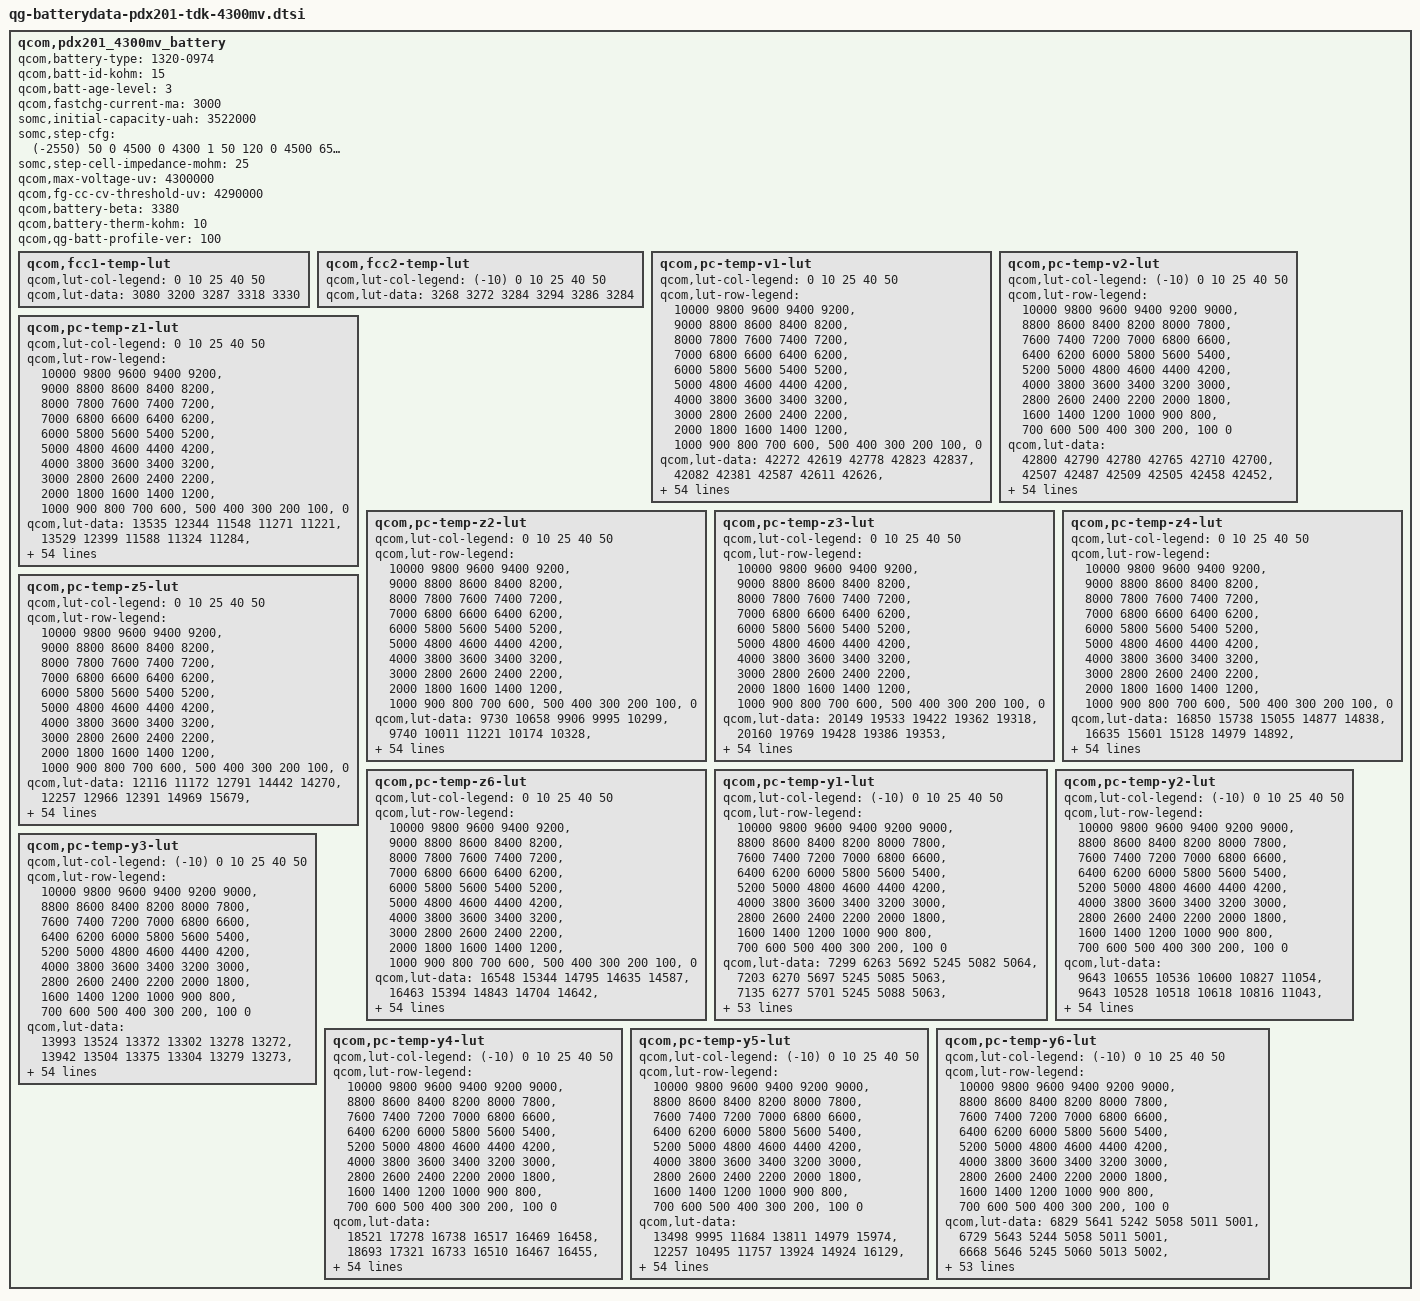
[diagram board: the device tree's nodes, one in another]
// SPDX-License-Identifier: GPL-2.0-only
/*
 * Copyright (c) 2019, The Linux Foundation. All rights reserved.
 */

qcom,pdx201_4300mv_battery {
	/* Added or Modified by SOMC */
	qcom,battery-type = "1320-0974";
	qcom,batt-id-kohm = <15>;
	qcom,batt-age-level = <3>;
	qcom,fastchg-current-ma = <3000>;
	somc,initial-capacity-uah = <3522000>;
	somc,step-cfg = <
		(-2550) 50    0 4500    0 4300 1
		   50  120    0 4500  650 4300 2
		  120  200    0 4100 2050 4300 3
		  120  200 4100 4200 1350 4300 3
		  120  200 4200 4500 1200 4300 3
		  200  450    0 4150 2750 4300 3
		  200  450 4150 4200 2050 4300 3
		  200  450 4200 4500 1350 4300 3
		  450  550    0 4500 1000 4200 4
		  550 2550    0 4500    0 4200 5
	>;
	somc,step-cell-impedance-mohm = <25>;

	/* Prepared by Qualcomm */
	/* 4176715_SoMC_Amuro2_3254mAh_averaged_MasterSlave_Sept16th2019 */
	qcom,max-voltage-uv = <4300000>;
	qcom,fg-cc-cv-threshold-uv = <4290000>;
	/* qcom,fastchg-current-ma = <1500>; */
	/* qcom,batt-id-kohm = <330>; */
	qcom,battery-beta = <3380>;
	qcom,battery-therm-kohm = <10>;
	/* qcom,battery-type = "4176715_SoMC_Amuro2_3254mAh_averaged_MasterSlave_Sept16th2019"; */
	qcom,qg-batt-profile-ver = <100>;

	qcom,fcc1-temp-lut {
		qcom,lut-col-legend = <0 10 25 40 50>;
		qcom,lut-data = <3080 3200 3287 3318 3330>;
	};

	qcom,fcc2-temp-lut {
		qcom,lut-col-legend = <(-10) 0 10 25 40 50>;
		qcom,lut-data = <3268 3272 3284 3294 3286 3284>;
	};

	qcom,pc-temp-v1-lut {
		qcom,lut-col-legend = <0 10 25 40 50>;
		qcom,lut-row-legend = <10000 9800 9600 9400 9200>,
			<9000 8800 8600 8400 8200>,
			<8000 7800 7600 7400 7200>,
			<7000 6800 6600 6400 6200>,
			<6000 5800 5600 5400 5200>,
			<5000 4800 4600 4400 4200>,
			<4000 3800 3600 3400 3200>,
			<3000 2800 2600 2400 2200>,
			<2000 1800 1600 1400 1200>,
			<1000 900 800 700 600>,
			<500 400 300 200 100>,
			<0>;
		qcom,lut-data = <42272 42619 42778 42823 42837>,
			<42082 42381 42587 42611 42626>,
			<41894 42162 42359 42397 42415>,
			<41706 41964 42130 42180 42200>,
			<41514 41775 41918 41967 41988>,
			<41341 41578 41712 41756 41780>,
			<41214 41380 41509 41549 41573>,
			<41105 41211 41305 41342 41367>,
			<40944 41092 41124 41144 41164>,
			<40609 40969 40992 40972 40968>,
			<40246 40739 40864 40819 40781>,
			<40040 40372 40651 40642 40595>,
			<39901 40092 40314 40404 40409>,
			<39788 39946 40061 40171 40228>,
			<39689 39832 39944 40010 40061>,
			<39603 39727 39851 39882 39906>,
			<39509 39635 39734 39750 39755>,
			<39402 39535 39601 39613 39615>,
			<39292 39414 39460 39466 39471>,
			<39184 39279 39314 39297 39306>,
			<39077 39134 39156 39113 39125>,
			<38973 38975 38962 38942 38955>,
			<38869 38819 38731 38770 38789>,
			<38768 38660 38578 38624 38641>,
			<38670 38510 38498 38524 38531>,
			<38573 38423 38437 38443 38441>,
			<38486 38372 38375 38363 38355>,
			<38419 38331 38318 38286 38272>,
			<38362 38293 38262 38215 38197>,
			<38318 38258 38208 38151 38130>,
			<38283 38225 38158 38094 38071>,
			<38255 38194 38115 38046 38018>,
			<38231 38164 38078 38006 37972>,
			<38212 38137 38043 37966 37927>,
			<38193 38112 38013 37928 37882>,
			<38168 38083 37981 37888 37836>,
			<38139 38051 37944 37841 37782>,
			<38099 38011 37904 37787 37722>,
			<38031 37950 37846 37721 37651>,
			<37943 37858 37755 37637 37569>,
			<37844 37755 37646 37538 37473>,
			<37727 37639 37531 37424 37359>,
			<37595 37510 37401 37295 37228>,
			<37449 37362 37254 37150 37082>,
			<37342 37251 37137 37034 36968>,
			<37279 37184 37069 36969 36906>,
			<37257 37163 37052 36954 36889>,
			<37238 37145 37040 36940 36875>,
			<37206 37123 37018 36915 36848>,
			<37084 37032 36919 36796 36711>,
			<36755 36717 36609 36478 36385>,
			<36307 36278 36178 36042 35948>,
			<35743 35718 35619 35483 35387>,
			<34994 34955 34864 34723 34627>,
			<33801 33785 33698 33556 33460>,
			<30000 30000 30000 30000 30000>;
	};

	qcom,pc-temp-v2-lut {
		qcom,lut-col-legend = <(-10) 0 10 25 40 50>;
		qcom,lut-row-legend = <10000 9800 9600 9400 9200 9000>,
			<8800 8600 8400 8200 8000 7800>,
			<7600 7400 7200 7000 6800 6600>,
			<6400 6200 6000 5800 5600 5400>,
			<5200 5000 4800 4600 4400 4200>,
			<4000 3800 3600 3400 3200 3000>,
			<2800 2600 2400 2200 2000 1800>,
			<1600 1400 1200 1000 900 800>,
			<700 600 500 400 300 200>,
			<100 0>;
		qcom,lut-data = <42800 42790 42780 42765 42710 42700>,
			<42507 42487 42509 42505 42458 42452>,
			<42226 42213 42256 42261 42219 42216>,
			<41949 41971 42027 42034 41995 41992>,
			<41664 41758 41818 41824 41783 41780>,
			<41456 41552 41615 41618 41577 41573>,
			<41354 41334 41403 41407 41371 41368>,
			<41272 41127 41201 41204 41170 41167>,
			<41134 40974 41038 41029 40978 40972>,
			<40922 40864 40910 40877 40797 40781>,
			<40655 40719 40748 40701 40608 40594>,
			<40243 40411 40466 40445 40394 40408>,
			<39810 40044 40151 40181 40184 40228>,
			<39613 39812 39933 39997 40021 40062>,
			<39513 39648 39762 39853 39889 39906>,
			<39406 39503 39610 39720 39755 39754>,
			<39270 39370 39479 39601 39614 39608>,
			<39106 39243 39350 39477 39467 39460>,
			<38848 39097 39190 39313 39299 39293>,
			<38447 38935 39004 39113 39109 39109>,
			<38205 38783 38838 38926 38927 38930>,
			<38138 38649 38698 38752 38751 38755>,
			<38095 38524 38575 38600 38594 38597>,
			<38051 38398 38466 38483 38476 38478>,
			<38012 38272 38370 38385 38378 38379>,
			<37973 38155 38282 38296 38290 38290>,
			<37933 38037 38202 38214 38208 38206>,
			<37894 37940 38126 38140 38134 38129>,
			<37856 37892 38045 38071 38065 38059>,
			<37819 37862 37962 38007 38001 37995>,
			<37781 37833 37899 37949 37943 37936>,
			<37745 37803 37851 37897 37892 37885>,
			<37708 37772 37810 37847 37841 37832>,
			<37671 37737 37771 37797 37779 37765>,
			<37633 37700 37735 37747 37711 37686>,
			<37592 37660 37696 37690 37636 37598>,
			<37550 37621 37655 37625 37551 37498>,
			<37502 37577 37608 37557 37468 37402>,
			<37440 37519 37550 37492 37399 37330>,
			<37364 37448 37480 37424 37335 37266>,
			<37285 37367 37400 37342 37257 37189>,
			<37203 37268 37300 37240 37157 37091>,
			<37123 37157 37184 37124 37043 36977>,
			<37051 37034 37052 36998 36915 36849>,
			<36980 36935 36943 36902 36832 36776>,
			<36900 36872 36899 36874 36809 36752>,
			<36856 36840 36881 36857 36793 36734>,
			<36804 36803 36858 36830 36766 36711>,
			<36732 36748 36816 36782 36712 36651>,
			<36587 36624 36701 36618 36533 36451>,
			<36311 36343 36389 36246 36165 36071>,
			<35881 35898 35915 35768 35676 35578>,
			<35287 35304 35313 35148 35051 34948>,
			<34450 34497 34516 34293 34196 34090>,
			<33193 33338 33386 33060 32908 32784>,
			<29549 29531 29522 29521 29519 29517>;
	};

	qcom,pc-temp-z1-lut {
		qcom,lut-col-legend = <0 10 25 40 50>;
		qcom,lut-row-legend = <10000 9800 9600 9400 9200>,
			<9000 8800 8600 8400 8200>,
			<8000 7800 7600 7400 7200>,
			<7000 6800 6600 6400 6200>,
			<6000 5800 5600 5400 5200>,
			<5000 4800 4600 4400 4200>,
			<4000 3800 3600 3400 3200>,
			<3000 2800 2600 2400 2200>,
			<2000 1800 1600 1400 1200>,
			<1000 900 800 700 600>,
			<500 400 300 200 100>,
			<0>;
		qcom,lut-data = <13535 12344 11548 11271 11221>,
			<13529 12399 11588 11324 11284>,
			<13530 12417 11610 11344 11303>,
			<13538 12417 11621 11358 11314>,
			<13559 12418 11625 11365 11322>,
			<13576 12422 11628 11371 11328>,
			<13583 12433 11633 11374 11332>,
			<13589 12438 11638 11376 11333>,
			<13587 12437 11641 11377 11334>,
			<13576 12434 11640 11379 11335>,
			<13563 12426 11638 11381 11335>,
			<13548 12406 11633 11381 11335>,
			<13530 12392 11623 11379 11336>,
			<13515 12386 11618 11376 11337>,
			<13506 12383 11623 11378 11338>,
			<13498 12388 11631 11382 11340>,
			<13498 12409 11636 11384 11341>,
			<13521 12425 11640 11385 11342>,
			<13545 12431 11644 11386 11343>,
			<13542 12436 11646 11387 11343>,
			<13524 12439 11647 11388 11344>,
			<13514 12442 11651 11389 11344>,
			<13514 12443 11656 11391 11346>,
			<13513 12445 11660 11392 11347>,
			<13511 12447 11662 11394 11350>,
			<13506 12449 11664 11396 11353>,
			<13502 12455 11668 11398 11355>,
			<13511 12461 11673 11401 11357>,
			<13536 12466 11677 11404 11358>,
			<13553 12478 11680 11407 11360>,
			<13558 12480 11683 11410 11362>,
			<13559 12474 11687 11411 11363>,
			<13556 12469 11691 11412 11364>,
			<13542 12473 11694 11413 11364>,
			<13531 12483 11696 11415 11365>,
			<13546 12491 11698 11417 11365>,
			<13579 12498 11700 11417 11366>,
			<13593 12503 11702 11417 11367>,
			<13573 12509 11704 11418 11368>,
			<13547 12516 11705 11419 11369>,
			<13539 12521 11707 11420 11369>,
			<13535 12525 11710 11421 11370>,
			<13532 12528 11713 11421 11371>,
			<13533 12515 11714 11422 11371>,
			<13527 12522 11716 11422 11371>,
			<13539 12521 11722 11424 11372>,
			<13527 12528 11718 11423 11371>,
			<13548 12531 11719 11422 11370>,
			<13548 12503 11718 11423 11371>,
			<13512 12540 11723 11422 11372>,
			<13542 12558 11729 11425 11373>,
			<13606 12561 11737 11431 11379>,
			<13602 12586 11754 11440 11384>,
			<13636 12641 11783 11454 11394>,
			<13636 12641 11783 11454 11394>,
			<13636 12641 11783 11454 11394>;
	};

	qcom,pc-temp-z2-lut {
		qcom,lut-col-legend = <0 10 25 40 50>;
		qcom,lut-row-legend = <10000 9800 9600 9400 9200>,
			<9000 8800 8600 8400 8200>,
			<8000 7800 7600 7400 7200>,
			<7000 6800 6600 6400 6200>,
			<6000 5800 5600 5400 5200>,
			<5000 4800 4600 4400 4200>,
			<4000 3800 3600 3400 3200>,
			<3000 2800 2600 2400 2200>,
			<2000 1800 1600 1400 1200>,
			<1000 900 800 700 600>,
			<500 400 300 200 100>,
			<0>;
		qcom,lut-data = <9730 10658 9906 9995 10299>,
			<9740 10011 11221 10174 10328>,
			<9752 9800 10793 10559 10389>,
			<9768 9797 10388 10917 10473>,
			<9788 9796 10200 10935 10471>,
			<9806 9794 10038 10836 10367>,
			<9818 9793 10013 10769 10298>,
			<9829 9793 10006 10709 10302>,
			<9832 9808 10005 10639 10310>,
			<9819 9825 10137 10620 10315>,
			<9802 9830 10362 10619 10325>,
			<9797 9831 10488 10637 10333>,
			<9794 9834 10576 10781 10343>,
			<9794 9845 10606 10914 10360>,
			<9795 9865 10379 10744 10386>,
			<9797 9885 10085 10349 10425>,
			<9798 9910 10062 10235 10441>,
			<9794 9934 10120 10228 10427>,
			<9791 9957 10159 10223 10410>,
			<9795 9979 10172 10310 10415>,
			<9809 9998 10179 10481 10431>,
			<9823 10015 10173 10504 10436>,
			<9831 10028 10155 10336 10420>,
			<9839 10039 10148 10214 10406>,
			<9847 10048 10151 10243 10441>,
			<9859 10048 10157 10309 10518>,
			<9868 10036 10184 10371 10529>,
			<9871 10026 10239 10443 10464>,
			<9872 10026 10260 10477 10405>,
			<9873 10026 10256 10426 10350>,
			<9875 10027 10249 10357 10286>,
			<9876 10035 10240 10350 10279>,
			<9877 10043 10228 10361 10303>,
			<9877 10047 10225 10377 10339>,
			<9878 10051 10240 10429 10420>,
			<9881 10054 10258 10494 10510>,
			<9889 10058 10272 10537 10548>,
			<9899 10064 10285 10574 10571>,
			<9910 10074 10298 10594 10587>,
			<9924 10089 10317 10603 10610>,
			<9938 10097 10330 10607 10629>,
			<9952 10098 10333 10607 10626>,
			<9974 10099 10337 10607 10618>,
			<10018 10119 10348 10611 10592>,
			<10246 10244 10403 10595 10589>,
			<10258 10290 10437 10534 10643>,
			<10247 10285 10423 10543 10622>,
			<10247 10289 10419 10540 10650>,
			<10264 10312 10418 10585 10740>,
			<10290 10340 10500 10740 10681>,
			<10288 10334 10486 10573 10498>,
			<10213 10285 10449 10483 10386>,
			<10106 10265 10386 10438 10333>,
			<9771 10215 10290 10334 10278>,
			<9771 10215 10290 10334 10278>,
			<9771 10215 10290 10334 10278>;
	};

	qcom,pc-temp-z3-lut {
		qcom,lut-col-legend = <0 10 25 40 50>;
		qcom,lut-row-legend = <10000 9800 9600 9400 9200>,
			<9000 8800 8600 8400 8200>,
			<8000 7800 7600 7400 7200>,
			<7000 6800 6600 6400 6200>,
			<6000 5800 5600 5400 5200>,
			<5000 4800 4600 4400 4200>,
			<4000 3800 3600 3400 3200>,
			<3000 2800 2600 2400 2200>,
			<2000 1800 1600 1400 1200>,
			<1000 900 800 700 600>,
			<500 400 300 200 100>,
			<0>;
		qcom,lut-data = <20149 19533 19422 19362 19318>,
			<20160 19769 19428 19386 19353>,
			<20165 19845 19496 19415 19371>,
			<20161 19840 19545 19436 19382>,
			<20133 19835 19549 19448 19383>,
			<20093 19837 19550 19457 19377>,
			<20020 19844 19549 19459 19371>,
			<19916 19845 19542 19447 19368>,
			<19881 19795 19538 19428 19365>,
			<19943 19736 19543 19414 19359>,
			<20014 19737 19552 19401 19349>,
			<20016 19762 19559 19397 19343>,
			<19980 19776 19565 19401 19342>,
			<19947 19744 19567 19405 19342>,
			<19933 19694 19501 19394 19339>,
			<19922 19668 19416 19369 19332>,
			<19922 19651 19408 19361 19329>,
			<19952 19643 19422 19362 19327>,
			<19985 19648 19440 19364 19327>,
			<19991 19659 19465 19374 19332>,
			<19989 19677 19490 19391 19345>,
			<19988 19712 19502 19394 19349>,
			<19993 19741 19510 19379 19332>,
			<20000 19752 19512 19364 19318>,
			<20006 19761 19499 19358 19321>,
			<20015 19760 19482 19354 19332>,
			<20021 19744 19474 19359 19345>,
			<20019 19725 19468 19389 19364>,
			<20010 19710 19468 19411 19375>,
			<20001 19697 19492 19415 19374>,
			<19990 19691 19515 19417 19368>,
			<19978 19690 19516 19415 19365>,
			<19967 19689 19513 19406 19360>,
			<19955 19690 19509 19398 19356>,
			<19944 19691 19502 19392 19354>,
			<19935 19691 19496 19388 19351>,
			<19928 19688 19492 19388 19349>,
			<19921 19684 19488 19389 19347>,
			<19914 19679 19485 19390 19345>,
			<19906 19672 19480 19382 19342>,
			<19894 19666 19476 19375 19340>,
			<19874 19662 19473 19373 19340>,
			<19850 19656 19469 19373 19341>,
			<19813 19639 19465 19370 19342>,
			<19676 19573 19445 19362 19339>,
			<19655 19544 19427 19351 19327>,
			<19649 19540 19426 19344 19325>,
			<19638 19537 19414 19340 19323>,
			<19620 19529 19409 19335 19315>,
			<19612 19516 19396 19327 19330>,
			<19613 19513 19397 19342 19343>,
			<19620 19516 19395 19346 19350>,
			<19575 19481 19394 19347 19352>,
			<19417 19465 19380 19357 19359>,
			<19417 19465 19380 19357 19359>,
			<19417 19465 19380 19357 19359>;
	};

	qcom,pc-temp-z4-lut {
		qcom,lut-col-legend = <0 10 25 40 50>;
		qcom,lut-row-legend = <10000 9800 9600 9400 9200>,
			<9000 8800 8600 8400 8200>,
			<8000 7800 7600 7400 7200>,
			<7000 6800 6600 6400 6200>,
			<6000 5800 5600 5400 5200>,
			<5000 4800 4600 4400 4200>,
			<4000 3800 3600 3400 3200>,
			<3000 2800 2600 2400 2200>,
			<2000 1800 1600 1400 1200>,
			<1000 900 800 700 600>,
			<500 400 300 200 100>,
			<0>;
		qcom,lut-data = <16850 15738 15055 14877 14838>,
			<16635 15601 15128 14979 14892>,
			<16450 15482 15066 14947 14898>,
			<16302 15375 15003 14880 14859>,
			<16178 15281 14964 14833 14829>,
			<16072 15204 14929 14792 14806>,
			<15983 15137 14899 14770 14788>,
			<15904 15086 14875 14763 14775>,
			<15824 15049 14844 14758 14765>,
			<15737 15017 14777 14751 14757>,
			<15649 14983 14709 14737 14751>,
			<15570 14947 14698 14724 14744>,
			<15497 14928 14701 14715 14733>,
			<15427 14924 14705 14708 14721>,
			<15363 14921 14751 14710 14711>,
			<15303 14914 14807 14714 14703>,
			<15241 14900 14807 14710 14695>,
			<15171 14886 14780 14697 14686>,
			<15111 14875 14759 14689 14680>,
			<15075 14866 14745 14700 14689>,
			<15048 14865 14736 14730 14720>,
			<15032 14870 14769 14766 14756>,
			<15025 14879 14877 14838 14821>,
			<15020 14915 14925 14887 14870>,
			<15020 14968 14922 14885 14862>,
			<15029 14981 14916 14876 14836>,
			<15040 14979 14908 14856 14807>,
			<15049 14975 14896 14807 14769>,
			<15058 14969 14878 14764 14739>,
			<15061 14962 14837 14741 14723>,
			<15060 14953 14798 14725 14712>,
			<15058 14939 14783 14716 14702>,
			<15054 14924 14773 14709 14693>,
			<15048 14912 14770 14707 14689>,
			<15040 14901 14769 14709 14693>,
			<15031 14897 14769 14712 14701>,
			<15022 14897 14771 14719 14714>,
			<15016 14899 14777 14730 14732>,
			<15014 14904 14786 14741 14739>,
			<15012 14915 14802 14751 14739>,
			<15009 14920 14813 14758 14737>,
			<15003 14913 14812 14756 14733>,
			<14991 14901 14809 14751 14727>,
			<14960 14886 14805 14755 14730>,
			<14863 14829 14781 14748 14727>,
			<14847 14791 14738 14718 14702>,
			<14841 14781 14726 14705 14685>,
			<14836 14773 14720 14686 14661>,
			<14828 14768 14714 14682 14661>,
			<14828 14777 14740 14715 14673>,
			<14849 14798 14759 14714 14667>,
			<14853 14801 14763 14710 14662>,
			<14903 14827 14763 14707 14658>,
			<15068 14829 14772 14694 14650>,
			<15068 14829 14772 14694 14650>,
			<15068 14829 14772 14694 14650>;
	};

	qcom,pc-temp-z5-lut {
		qcom,lut-col-legend = <0 10 25 40 50>;
		qcom,lut-row-legend = <10000 9800 9600 9400 9200>,
			<9000 8800 8600 8400 8200>,
			<8000 7800 7600 7400 7200>,
			<7000 6800 6600 6400 6200>,
			<6000 5800 5600 5400 5200>,
			<5000 4800 4600 4400 4200>,
			<4000 3800 3600 3400 3200>,
			<3000 2800 2600 2400 2200>,
			<2000 1800 1600 1400 1200>,
			<1000 900 800 700 600>,
			<500 400 300 200 100>,
			<0>;
		qcom,lut-data = <12116 11172 12791 14442 14270>,
			<12257 12966 12391 14969 15679>,
			<12370 13735 13760 15632 16042>,
			<12446 13926 15068 16622 16541>,
			<12524 14076 15586 17782 16686>,
			<12563 14457 15957 19271 16487>,
			<12430 15064 16257 19970 16372>,
			<12160 15286 16494 19749 16541>,
			<12080 14743 16916 19278 16753>,
			<12619 14111 19508 19157 16718>,
			<13239 14565 23162 19073 16329>,
			<13324 16425 24639 19125 16098>,
			<13315 17403 25404 20362 16493>,
			<13309 16616 25581 21617 17043>,
			<13373 15555 20730 20633 17168>,
			<13556 15407 14417 18173 17198>,
			<13870 15557 13783 17779 17268>,
			<14845 15800 14811 18688 17770>,
			<16111 16482 16493 20185 18756>,
			<17136 17816 21366 25028 21324>,
			<18104 20260 26692 32419 25830>,
			<19163 25759 28874 33288 26876>,
			<20447 29897 30570 25880 21281>,
			<21867 31213 31004 19178 15973>,
			<23302 32192 26558 16726 15122>,
			<25064 31958 20940 15162 14705>,
			<26242 28196 18637 15133 14851>,
			<26194 24240 17146 16495 16664>,
			<25789 22302 16823 18245 18294>,
			<25284 20876 18599 20310 19044>,
			<24552 20533 20951 22477 19937>,
			<23702 20651 22437 23954 20991>,
			<23033 20865 23677 25145 22752>,
			<22377 21344 24266 25699 23974>,
			<21981 22155 24556 25869 24628>,
			<21997 22571 24693 25956 25068>,
			<22148 22735 24390 25825 24399>,
			<22335 22826 23528 25278 21819>,
			<22985 22649 22574 24395 19766>,
			<23692 22135 21304 21524 18393>,
			<23719 21903 20291 18776 17503>,
			<23385 22074 19890 18220 17304>,
			<23406 22200 19644 17936 17191>,
			<24180 22186 19323 17136 16799>,
			<25559 22646 19572 16913 16429>,
			<24591 22988 20610 17363 16350>,
			<23739 22871 20861 17023 17015>,
			<22738 23262 19713 17693 18911>,
			<21972 22830 19890 17874 18397>,
			<21910 21126 17533 15017 17015>,
			<20615 19108 15996 14868 17764>,
			<19060 18220 15370 14968 18751>,
			<15601 15278 14926 14908 19396>,
			<11826 14317 13982 15783 21490>,
			<11826 14317 13982 15783 21490>,
			<11826 14317 13982 15783 21490>;
	};

	qcom,pc-temp-z6-lut {
		qcom,lut-col-legend = <0 10 25 40 50>;
		qcom,lut-row-legend = <10000 9800 9600 9400 9200>,
			<9000 8800 8600 8400 8200>,
			<8000 7800 7600 7400 7200>,
			<7000 6800 6600 6400 6200>,
			<6000 5800 5600 5400 5200>,
			<5000 4800 4600 4400 4200>,
			<4000 3800 3600 3400 3200>,
			<3000 2800 2600 2400 2200>,
			<2000 1800 1600 1400 1200>,
			<1000 900 800 700 600>,
			<500 400 300 200 100>,
			<0>;
		qcom,lut-data = <16548 15344 14795 14635 14587>,
			<16463 15394 14843 14704 14642>,
			<16384 15402 14851 14703 14651>,
			<16310 15358 14854 14694 14646>,
			<16243 15301 14845 14686 14639>,
			<16176 15269 14826 14675 14627>,
			<16093 15245 14811 14664 14616>,
			<16006 15217 14798 14653 14608>,
			<15959 15172 14783 14642 14602>,
			<15942 15130 14757 14631 14595>,
			<15928 15116 14733 14617 14587>,
			<15898 15109 14730 14611 14580>,
			<15844 15100 14733 14609 14575>,
			<15793 15080 14735 14607 14569>,
			<15756 15056 14720 14601 14563>,
			<15725 15040 14699 14589 14556>,
			<15705 15027 14693 14581 14550>,
			<15693 15021 14690 14576 14545>,
			<15683 15022 14689 14573 14542>,
			<15671 15023 14694 14582 14548>,
			<15659 15029 14704 14604 14569>,
			<15653 15048 14729 14622 14586>,
			<15654 15072 14779 14645 14606>,
			<15656 15098 14800 14659 14620>,
			<15660 15123 14793 14656 14619>,
			<15670 15128 14782 14650 14614>,
			<15679 15120 14774 14645 14609>,
			<15679 15109 14767 14639 14603>,
			<15679 15101 14761 14634 14596>,
			<15678 15092 14756 14627 14589>,
			<15675 15085 14751 14621 14581>,
			<15669 15078 14746 14614 14574>,
			<15663 15073 14741 14606 14567>,
			<15655 15069 14736 14602 14564>,
			<15648 15067 14732 14600 14564>,
			<15641 15065 14729 14598 14565>,
			<15634 15065 14729 14600 14568>,
			<15630 15065 14730 14607 14575>,
			<15626 15065 14731 14610 14578>,
			<15623 15068 14735 14610 14576>,
			<15616 15069 14739 14610 14574>,
			<15603 15065 14738 14609 14572>,
			<15585 15058 14734 14606 14570>,
			<15553 15044 14730 14606 14572>,
			<15441 14988 14710 14600 14569>,
			<15422 14957 14683 14580 14552>,
			<15415 14951 14677 14571 14543>,
			<15407 14945 14667 14561 14532>,
			<15399 14940 14662 14556 14527>,
			<15401 14941 14667 14566 14541>,
			<15420 14953 14678 14574 14547>,
			<15436 14961 14681 14577 14549>,
			<15454 14967 14685 14578 14550>,
			<15479 14978 14688 14580 14553>,
			<15479 14978 14688 14580 14553>,
			<15479 14978 14688 14580 14553>;
	};

	qcom,pc-temp-y1-lut {
		qcom,lut-col-legend = <(-10) 0 10 25 40 50>;
		qcom,lut-row-legend = <10000 9800 9600 9400 9200 9000>,
			<8800 8600 8400 8200 8000 7800>,
			<7600 7400 7200 7000 6800 6600>,
			<6400 6200 6000 5800 5600 5400>,
			<5200 5000 4800 4600 4400 4200>,
			<4000 3800 3600 3400 3200 3000>,
			<2800 2600 2400 2200 2000 1800>,
			<1600 1400 1200 1000 900 800>,
			<700 600 500 400 300 200>,
			<100 0>;
		qcom,lut-data = <7299 6263 5692 5245 5082 5064>,
			<7203 6270 5697 5245 5085 5063>,
			<7135 6277 5701 5245 5088 5063>,
			<7092 6281 5702 5244 5090 5063>,
			<7068 6283 5703 5243 5091 5063>,
			<7061 6282 5703 5242 5091 5063>,
			<7087 6276 5698 5241 5090 5063>,
			<7124 6269 5691 5239 5089 5063>,
			<7119 6266 5689 5237 5089 5063>,
			<7065 6264 5688 5236 5088 5062>,
			<7034 6264 5688 5235 5089 5062>,
			<7052 6257 5686 5236 5089 5063>,
			<7078 6247 5685 5238 5089 5065>,
			<7079 6252 5685 5241 5090 5065>,
			<7060 6270 5687 5245 5090 5064>,
			<7049 6281 5688 5247 5091 5063>,
			<7060 6278 5688 5246 5092 5063>,
			<7073 6273 5688 5244 5093 5063>,
			<7069 6271 5688 5245 5093 5064>,
			<7051 6266 5690 5246 5092 5064>,
			<7040 6264 5693 5248 5092 5065>,
			<7049 6268 5700 5251 5092 5066>,
			<7065 6272 5706 5254 5092 5067>,
			<7083 6278 5706 5255 5094 5067>,
			<7121 6292 5704 5256 5096 5068>,
			<7138 6302 5703 5258 5097 5069>,
			<7107 6307 5705 5262 5098 5070>,
			<7067 6311 5708 5266 5099 5070>,
			<7059 6311 5713 5268 5100 5071>,
			<7061 6309 5722 5270 5102 5073>,
			<7057 6308 5726 5273 5103 5074>,
			<7037 6298 5728 5277 5105 5075>,
			<7016 6287 5729 5282 5106 5076>,
			<7009 6285 5739 5286 5109 5077>,
			<7006 6286 5758 5290 5112 5077>,
			<7003 6286 5764 5293 5114 5078>,
			<7000 6291 5763 5297 5113 5080>,
			<6998 6294 5761 5299 5113 5081>,
			<7004 6296 5760 5301 5114 5082>,
			<7026 6301 5759 5301 5115 5082>,
			<7037 6306 5760 5303 5115 5082>,
			<7020 6318 5774 5305 5116 5082>,
			<7007 6318 5783 5307 5116 5082>,
			<7042 6291 5782 5309 5117 5082>,
			<7021 6294 5778 5310 5118 5082>,
			<7025 6299 5781 5308 5118 5081>,
			<7053 6310 5772 5313 5119 5082>,
			<7040 6325 5781 5313 5119 5083>,
			<7031 6307 5779 5313 5119 5084>,
			<7029 6308 5777 5316 5119 5084>,
			<7109 6317 5790 5322 5121 5085>,
			<7125 6334 5813 5331 5128 5087>,
			<7111 6364 5825 5345 5131 5092>,
			<7216 6388 5874 5362 5140 5098>,
			<7216 6388 5874 5362 5140 5098>,
			<7216 6388 5874 5362 5140 5098>;
	};

	qcom,pc-temp-y2-lut {
		qcom,lut-col-legend = <(-10) 0 10 25 40 50>;
		qcom,lut-row-legend = <10000 9800 9600 9400 9200 9000>,
			<8800 8600 8400 8200 8000 7800>,
			<7600 7400 7200 7000 6800 6600>,
			<6400 6200 6000 5800 5600 5400>,
			<5200 5000 4800 4600 4400 4200>,
			<4000 3800 3600 3400 3200 3000>,
			<2800 2600 2400 2200 2000 1800>,
			<1600 1400 1200 1000 900 800>,
			<700 600 500 400 300 200>,
			<100 0>;
		qcom,lut-data = <9643 10655 10536 10600 10827 11054>,
			<9643 10528 10518 10618 10816 11043>,
			<9912 10439 10499 10633 10801 11035>,
			<10540 10382 10481 10645 10785 11027>,
			<10916 10351 10465 10652 10773 11020>,
			<11037 10343 10454 10655 10768 11011>,
			<10751 10367 10448 10653 10770 11000>,
			<10331 10414 10442 10649 10774 10991>,
			<10302 10460 10435 10645 10771 10985>,
			<10503 10512 10427 10637 10754 10969>,
			<10622 10536 10424 10634 10748 10958>,
			<10616 10522 10471 10663 10827 10955>,
			<10604 10501 10541 10706 10925 10953>,
			<10593 10511 10572 10729 10915 10947>,
			<10579 10573 10589 10745 10832 10940>,
			<10556 10631 10607 10763 10794 10944>,
			<10441 10667 10633 10784 10892 10988>,
			<10249 10698 10662 10807 11020 11041>,
			<10044 10726 10687 10830 11046 11058>,
			<9793 10751 10712 10853 11022 11068>,
			<9673 10779 10740 10875 11005 11071>,
			<9664 10821 10775 10895 10991 11079>,
			<9659 10856 10811 10918 10989 11094>,
			<9657 10826 10841 10952 11021 11116>,
			<9655 10708 10869 10997 11072 11151>,
			<9654 10651 10902 11041 11114 11183>,
			<9654 10667 10952 11088 11142 11214>,
			<9653 10685 10989 11126 11169 11241>,
			<9653 10672 10983 11147 11202 11262>,
			<9653 10617 10957 11166 11239 11286>,
			<9653 10563 10931 11186 11285 11312>,
			<9653 10423 10908 11214 11351 11368>,
			<9653 10252 10879 11235 11402 11437>,
			<9653 10090 10823 11243 11425 11522>,
			<9653 9812 10739 11244 11445 11629>,
			<9653 9698 10677 11233 11469 11661>,
			<9653 9685 10633 11190 11505 11651>,
			<9653 9677 10597 11151 11529 11636>,
			<9653 9671 10568 11135 11513 11604>,
			<9653 9667 10542 11121 11469 11550>,
			<9653 9664 10514 11104 11422 11520>,
			<9653 9661 10482 11068 11367 11524>,
			<9653 9659 10454 11042 11358 11548>,
			<9653 9658 10429 11016 11390 11573>,
			<9652 9657 10386 10969 11285 11401>,
			<9653 9658 10434 10996 11359 11363>,
			<9652 9657 10414 11024 11287 11375>,
			<9652 9656 10399 10987 11254 11279>,
			<9652 9655 10383 10961 11250 11176>,
			<9652 9655 10375 10940 11216 11190>,
			<9652 9654 10344 10908 11146 11125>,
			<9651 9654 10303 10829 11070 11050>,
			<9650 9653 10253 10756 10973 10974>,
			<9649 9651 10212 10710 10879 10864>,
			<9649 9651 10212 10710 10879 10864>,
			<9649 9651 10212 10710 10879 10864>;
	};

	qcom,pc-temp-y3-lut {
		qcom,lut-col-legend = <(-10) 0 10 25 40 50>;
		qcom,lut-row-legend = <10000 9800 9600 9400 9200 9000>,
			<8800 8600 8400 8200 8000 7800>,
			<7600 7400 7200 7000 6800 6600>,
			<6400 6200 6000 5800 5600 5400>,
			<5200 5000 4800 4600 4400 4200>,
			<4000 3800 3600 3400 3200 3000>,
			<2800 2600 2400 2200 2000 1800>,
			<1600 1400 1200 1000 900 800>,
			<700 600 500 400 300 200>,
			<100 0>;
		qcom,lut-data = <13993 13524 13372 13302 13278 13272>,
			<13942 13504 13375 13304 13279 13273>,
			<13831 13492 13379 13306 13280 13274>,
			<13701 13486 13383 13307 13281 13275>,
			<13593 13483 13386 13308 13281 13276>,
			<13550 13483 13387 13308 13282 13277>,
			<13551 13495 13388 13308 13282 13278>,
			<13553 13512 13389 13307 13283 13278>,
			<13578 13518 13393 13309 13284 13278>,
			<13681 13520 13408 13317 13287 13278>,
			<13741 13521 13415 13322 13289 13278>,
			<13667 13503 13407 13318 13289 13278>,
			<13551 13476 13397 13313 13289 13277>,
			<13504 13466 13397 13313 13289 13277>,
			<13481 13461 13400 13317 13286 13279>,
			<13466 13458 13402 13320 13285 13281>,
			<13456 13456 13401 13323 13289 13282>,
			<13449 13454 13399 13325 13293 13283>,
			<13449 13449 13393 13324 13293 13283>,
			<13453 13437 13376 13321 13291 13282>,
			<13461 13423 13363 13318 13289 13281>,
			<13513 13406 13353 13310 13284 13278>,
			<13606 13391 13347 13303 13279 13275>,
			<13715 13386 13347 13301 13279 13275>,
			<13858 13384 13347 13300 13279 13275>,
			<13990 13382 13347 13300 13279 13275>,
			<14098 13377 13345 13300 13280 13275>,
			<14193 13373 13341 13300 13281 13275>,
			<14271 13378 13338 13301 13281 13275>,
			<14337 13396 13335 13302 13282 13276>,
			<14396 13405 13335 13302 13283 13277>,
			<14450 13403 13338 13301 13284 13278>,
			<14499 13399 13344 13301 13285 13278>,
			<14547 13402 13350 13301 13284 13278>,
			<14595 13414 13357 13302 13282 13277>,
			<14642 13427 13365 13302 13280 13276>,
			<14691 13445 13372 13301 13279 13273>,
			<14740 13466 13378 13301 13279 13271>,
			<14788 13487 13380 13301 13279 13271>,
			<14836 13509 13382 13302 13279 13272>,
			<14888 13538 13384 13303 13279 13273>,
			<14943 13586 13387 13302 13279 13273>,
			<15008 13647 13390 13303 13279 13274>,
			<15090 13723 13393 13303 13279 13273>,
			<15180 13824 13395 13307 13280 13274>,
			<14980 13738 13386 13305 13283 13276>,
			<15100 13794 13393 13308 13284 13277>,
			<15234 13884 13398 13308 13285 13285>,
			<15375 13974 13410 13316 13291 13286>,
			<15520 14069 13421 13315 13291 13282>,
			<15692 14157 13420 13312 13292 13282>,
			<16050 14347 13430 13325 13293 13284>,
			<16678 14656 13453 13332 13296 13288>,
			<17404 15109 13487 13339 13300 13291>,
			<17404 15109 13487 13339 13300 13291>,
			<17404 15109 13487 13339 13300 13291>;
	};

	qcom,pc-temp-y4-lut {
		qcom,lut-col-legend = <(-10) 0 10 25 40 50>;
		qcom,lut-row-legend = <10000 9800 9600 9400 9200 9000>,
			<8800 8600 8400 8200 8000 7800>,
			<7600 7400 7200 7000 6800 6600>,
			<6400 6200 6000 5800 5600 5400>,
			<5200 5000 4800 4600 4400 4200>,
			<4000 3800 3600 3400 3200 3000>,
			<2800 2600 2400 2200 2000 1800>,
			<1600 1400 1200 1000 900 800>,
			<700 600 500 400 300 200>,
			<100 0>;
		qcom,lut-data = <18521 17278 16738 16517 16469 16458>,
			<18693 17321 16733 16510 16467 16455>,
			<18859 17365 16732 16507 16467 16454>,
			<19019 17405 16734 16509 16469 16455>,
			<19173 17432 16738 16514 16472 16456>,
			<19320 17443 16743 16520 16475 16458>,
			<19491 17433 16750 16530 16480 16461>,
			<19632 17420 16759 16542 16486 16464>,
			<19582 17457 16782 16555 16492 16469>,
			<19208 17635 16829 16568 16499 16476>,
			<18822 17739 16853 16576 16506 16483>,
			<18496 17564 16837 16579 16510 16492>,
			<18242 17321 16816 16581 16515 16501>,
			<18227 17297 16823 16593 16526 16509>,
			<18309 17348 16858 16623 16547 16517>,
			<18354 17377 16877 16651 16566 16527>,
			<18280 17377 16874 16678 16583 16544>,
			<18116 17373 16866 16696 16596 16559>,
			<17830 17353 16838 16684 16594 16560>,
			<17295 17282 16772 16640 16578 16551>,
			<17033 17220 16736 16600 16561 16538>,
			<17050 17189 16725 16556 16520 16504>,
			<17077 17158 16720 16525 16483 16471>,
			<17091 17092 16718 16524 16480 16467>,
			<17099 16971 16718 16526 16480 16466>,
			<17108 16865 16718 16530 16481 16467>,
			<17119 16774 16728 16538 16487 16471>,
			<17131 16711 16737 16547 16495 16479>,
			<17143 16721 16718 16556 16504 16487>,
			<17155 16779 16667 16567 16515 16498>,
			<17169 16840 16648 16579 16528 16509>,
			<17186 16901 16650 16596 16545 16524>,
			<17203 16962 16652 16606 16557 16535>,
			<17214 17016 16667 16603 16554 16530>,
			<17223 17070 16701 16595 16543 16516>,
			<17226 17103 16728 16586 16532 16504>,
			<17225 17123 16748 16571 16512 16490>,
			<17224 17138 16765 16563 16498 16481>,
			<17218 17151 16780 16564 16501 16484>,
			<17200 17162 16793 16568 16508 16488>,
			<17190 17165 16803 16570 16510 16489>,
			<17186 17160 16810 16571 16509 16487>,
			<17187 17155 16818 16576 16508 16485>,
			<17219 17134 16825 16581 16507 16483>,
			<17265 17117 16816 16557 16497 16479>,
			<17233 17098 16765 16560 16508 16491>,
			<17271 17138 16792 16575 16519 16497>,
			<17317 17195 16832 16601 16529 16498>,
			<17355 17288 16887 16616 16531 16512>,
			<17364 17308 16915 16602 16514 16490>,
			<17353 17298 16886 16584 16499 16478>,
			<17442 17295 16893 16613 16508 16486>,
			<17741 17333 16953 16653 16537 16512>,
			<18305 17550 17052 16738 16609 16586>,
			<18305 17550 17052 16738 16609 16586>,
			<18305 17550 17052 16738 16609 16586>;
	};

	qcom,pc-temp-y5-lut {
		qcom,lut-col-legend = <(-10) 0 10 25 40 50>;
		qcom,lut-row-legend = <10000 9800 9600 9400 9200 9000>,
			<8800 8600 8400 8200 8000 7800>,
			<7600 7400 7200 7000 6800 6600>,
			<6400 6200 6000 5800 5600 5400>,
			<5200 5000 4800 4600 4400 4200>,
			<4000 3800 3600 3400 3200 3000>,
			<2800 2600 2400 2200 2000 1800>,
			<1600 1400 1200 1000 900 800>,
			<700 600 500 400 300 200>,
			<100 0>;
		qcom,lut-data = <13498 9995 11684 13811 14979 15974>,
			<12257 10495 11757 13924 14924 16129>,
			<11411 10810 11836 13915 14809 16148>,
			<10893 10983 11909 13810 14642 16062>,
			<10634 11055 11961 13632 14433 15902>,
			<10565 11069 11980 13407 14190 15698>,
			<10758 10930 11964 13005 13815 15420>,
			<11215 10726 11943 12623 13472 15063>,
			<12054 10811 11949 12662 13505 14660>,
			<13815 11407 12002 13004 13836 14179>,
			<14761 11941 12087 13172 14014 13708>,
			<13688 12262 12320 12913 13860 13180>,
			<12177 12483 12686 12603 13561 12774>,
			<12077 12464 13075 12580 13157 12791>,
			<12787 12272 13534 12617 12567 13024>,
			<13613 12169 14006 12685 12322 13190>,
			<14601 12474 14602 12971 12604 13146>,
			<15450 12967 15059 13463 13133 13115>,
			<14957 13257 14929 14388 13911 13569>,
			<12498 13457 14318 15842 15052 14655>,
			<11082 13679 13798 16283 15467 15310>,
			<10977 13914 13397 15273 15026 15579>,
			<10925 14233 13136 14228 14514 15739>,
			<10947 15249 13246 13967 14363 15764>,
			<11062 17528 13654 13775 14268 15706>,
			<11155 18534 14002 13719 14209 15570>,
			<11197 16329 14224 13787 14238 14999>,
			<11233 13611 14490 13875 14317 14477>,
			<11269 13097 15206 14041 14366 14482>,
			<11307 12961 16338 14409 14461 14621>,
			<11334 12842 16705 14783 14621 14782>,
			<11353 12548 16640 15469 14967 14980>,
			<11371 12232 16518 16221 15388 15221>,
			<11405 11983 16139 16887 15822 15589>,
			<11491 11539 15435 17455 16243 16040>,
			<11590 11383 14997 17462 16347 16114>,
			<11744 11448 14780 16752 16092 15506>,
			<11874 11513 14563 16085 15838 14815>,
			<11853 11503 14207 15764 15590 14478>,
			<11727 11457 13781 15492 15105 14240>,
			<11593 11421 13459 15222 14738 14161>,
			<11445 11393 13218 14804 14458 14143>,
			<11346 11346 12961 14482 14313 14135>,
			<11303 11267 12731 14284 14359 14183>,
			<11340 11320 12694 15521 14739 14698>,
			<11349 11342 13127 15022 14412 13620>,
			<11413 11260 13090 14658 13870 13432>,
			<11523 11312 12897 13728 13571 15499>,
			<11851 11359 12912 14183 14552 15607>,
			<11971 11627 13217 14438 15167 14877>,
			<11840 11584 13291 14501 17189 15715>,
			<11185 11441 13264 16201 17067 16178>,
			<10599 11341 13287 16674 17626 18230>,
			<10245 11039 13675 16596 17572 18099>,
			<10245 11039 13675 16596 17572 18099>,
			<10245 11039 13675 16596 17572 18099>;
	};

	qcom,pc-temp-y6-lut {
		qcom,lut-col-legend = <(-10) 0 10 25 40 50>;
		qcom,lut-row-legend = <10000 9800 9600 9400 9200 9000>,
			<8800 8600 8400 8200 8000 7800>,
			<7600 7400 7200 7000 6800 6600>,
			<6400 6200 6000 5800 5600 5400>,
			<5200 5000 4800 4600 4400 4200>,
			<4000 3800 3600 3400 3200 3000>,
			<2800 2600 2400 2200 2000 1800>,
			<1600 1400 1200 1000 900 800>,
			<700 600 500 400 300 200>,
			<100 0>;
		qcom,lut-data = <6829 5641 5242 5058 5011 5001>,
			<6729 5643 5244 5058 5011 5001>,
			<6668 5646 5245 5060 5013 5002>,
			<6637 5649 5247 5061 5014 5003>,
			<6626 5652 5249 5063 5015 5004>,
			<6624 5656 5252 5065 5017 5005>,
			<6663 5660 5254 5068 5018 5006>,
			<6719 5664 5256 5070 5020 5008>,
			<6724 5681 5265 5076 5023 5010>,
			<6694 5732 5287 5086 5027 5012>,
			<6648 5760 5299 5090 5030 5014>,
			<6520 5698 5288 5088 5032 5015>,
			<6377 5611 5274 5086 5034 5018>,
			<6364 5601 5276 5089 5036 5020>,
			<6399 5615 5289 5100 5040 5024>,
			<6418 5622 5295 5111 5045 5028>,
			<6410 5622 5293 5120 5053 5033>,
			<6390 5622 5289 5126 5059 5038>,
			<6337 5615 5277 5122 5058 5039>,
			<6204 5590 5247 5107 5052 5035>,
			<6137 5566 5228 5093 5045 5030>,
			<6236 5551 5219 5074 5030 5018>,
			<6407 5537 5214 5061 5016 5006>,
			<6546 5515 5214 5060 5014 5005>,
			<6679 5485 5215 5060 5014 5005>,
			<6788 5465 5216 5061 5015 5005>,
			<6871 5455 5218 5063 5017 5006>,
			<6940 5449 5220 5067 5020 5008>,
			<6999 5470 5214 5070 5023 5011>,
			<7050 5551 5199 5074 5027 5014>,
			<7094 5628 5195 5078 5031 5018>,
			<7135 5686 5200 5082 5037 5023>,
			<7172 5739 5209 5085 5041 5026>,
			<7209 5783 5224 5085 5039 5025>,
			<7244 5822 5245 5084 5035 5020>,
			<7280 5861 5264 5082 5030 5016>,
			<7317 5903 5281 5078 5024 5010>,
			<7353 5946 5296 5076 5020 5007>,
			<7386 5993 5309 5077 5021 5007>,
			<7418 6043 5321 5079 5023 5009>,
			<7453 6096 5334 5080 5024 5010>,
			<7495 6155 5348 5081 5024 5010>,
			<7545 6220 5364 5083 5023 5009>,
			<7616 6291 5380 5086 5023 5009>,
			<7693 6376 5387 5081 5021 5008>,
			<7548 6293 5344 5081 5026 5013>,
			<7643 6356 5364 5088 5030 5016>,
			<7754 6451 5386 5095 5034 5021>,
			<7872 6548 5423 5106 5039 5026>,
			<7986 6631 5451 5101 5034 5017>,
			<8117 6702 5456 5095 5031 5014>,
			<8452 6861 5491 5114 5035 5018>,
			<9077 7117 5570 5133 5046 5029>,
			<9849 7553 5671 5166 5070 5053>,
			<9849 7553 5671 5166 5070 5053>,
			<9849 7553 5671 5166 5070 5053>;
	};

};
